# ODS5010 register map
Vendor: OCS; Series: ODS5010; File version: 1.0
CPU: CM0plus r0p0, little endian, MPU, FPU, 4 interrupt priority bits
Registers are 32-bit, read-write, reset 0x0 unless marked. A register's access mark holds for its fields unless they carry their own. Offsets are from the block's base; lines under a group give offsets from that group; [hi:lo] are bit positions; {n}, {i} and the like mark numbered series; 'fields as' and 'values as' point back to an identical list; <NAME> marks a mode.

## Memory map
0x40001C00 TIM13 size 0x24 — Timer 13 Peripheral
0x40002000 TIM14 size 0x24 — Timer 14 Peripheral
0x40003000 IWDG size 0x14 — Independent Watchdog Timer
0x40003800 SPI0 size 0x100 — Serial Peripheral Interface (SPI0) Peripheral
0x40004000 UART0 size 0x30 — Universal Asynchronous Receiver/Transmitter 0
0x40004400 UART1 size 0x30 — Universal Asynchronous Receiver/Transmitter 1
0x40005400 I2C0 size 0x100 — Inter-Integrated Circuit (I2C0) Peripheral
0x40005800 I2C1 size 0x100 — Inter-Integrated Circuit (I2C1) Peripheral
0x40006000 HWMATH size 0x2C — Hardware Mathematical Module, including square root, division, sine and cosine operation functions with status flags
0x40006400 HALL size 0x24 — Hall Sensor
0x40006430 QEP size 0x14 — Quadrature Encoder Pulse
0x40007800 MISC size 0x1C — MISC Control Registers (CSA and Temperature Sensor)
0x40010C00 MCPWM size 0xD0 — Motor Control PWM
0x40012400 ADC size 0x9C — Analog-to-Digital Converter (ADC) Peripheral
0x40013800 SPI1 size 0x100 — Serial Peripheral Interface (SPI1) Peripheral
0x40014000 TIM15 size 0x24 — Timer 15 Peripheral
0x40014400 TIM16 size 0x24 — Timer 16 Peripheral
0x40020000 RCC size 0x80 — Reset and Clock Control (RCC) Module
0x40020400 SYSCFG size 0x400 — System Configuration (SYSCFG) Peripheral
0x40022000 FLASH size 0x100 — Flash Memory Controller Peripheral
0x48000000 GPIO_A size 0x90 — GPIO Port A
0x48000400 GPIO_B size 0x90 — GPIO Port B
0x48000800 GPIO_C size 0x90 — GPIO Port C

## GPIO_A — GPIO Port A
Base 0x48000000; register names take the prefix GPIO_A_
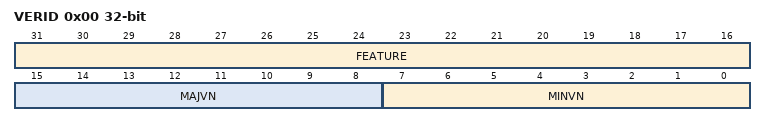
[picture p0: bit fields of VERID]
0x00 VERID ro — Version ID Register
  [31:16] FEATURE — Feature Identification
  [15:8] MAJVN — Major Version Number
  [7:0] MINVN — Minor Version Number
0x04 DR — Data Register
  [15:0] DR — Data Register Value
0x08 DRS — Data Set Register
  [15:0] DRS — Data Set Value
0x0C DRC — Data Clear Register
  [15:0] DRC — Data Clear Value
0x10 DRT — Data Toggle Register
  [15:0] DRT — Data Toggle Value
0x14 OES — Output Enable Set Register
  [15:0] OES — Output Enable Set Value
0x18 OEC — Output Enable Clear Register
  [15:0] OEC — Output Enable Clear Value
0x1C ITES — Interrupt Enable Set Register
  [15:0] ITES — Interrupt Enable Set Value
0x20 ITEC — Interrupt Enable Clear Register
  [15:0] ITEC — Interrupt Enable Clear Value
0x24 ITT0 — Interrupt Type for Pins 0-7
  [31:0] ITT0_7
0x28 ITT1 — Interrupt Type for Pins 8-15
  [31:0] ITT8_15
0x34 ITTC — Interrupt Type Control Register
  [15:0] ITTC — Interrupt Type Control Value
0x38 ITS — Interrupt Status Register
  [15:0] ITS — Interrupt Status Value
0x3C AF0 — Alternate Function for Pins 0-7
  [31:0] AF0_7
0x40 AF1 — Alternate Function for Pins 8-15
  [31:0] AF8_15
0x4C AFC — Alternate Function Control Register
  [15:0] AFC — Alternate Function Control Value
0x50 ANA — Analog Control Register
  [15:0] ANA — Analog Control Value
0x54 ANAC — Analog Control Configuration Register
  [15:0] ANAC — Analog Control Configuration Value
0x58 PU — Pull-up Register
  [15:0] PU — Pull-up Control Value
0x5C SPU — Strong Pull-up Register
  [15:0] SPU — Strong Pull-up Control Value
0x60 PUC — Pull-up Control Register
  [15:0] PUC — Pull-up Control Configuration Value
0x64 PD — Pull-down Register
  [15:0] PD — Pull-down Control Value
0x68 PDC — Pull-down Control Register
  [15:0] PDC — Pull-down Control Configuration Value
0x6C DRVS0 — Drive Strength for Pins 0-7
  [31:0] DRVS0_7
0x70 DRVS1 — Drive Strength for Pins 8-15
  [31:0] DRVS8_15
0x7C DRVC — Drive Strength Control Register
  [15:0] DRVC — Drive Strength Control Value
0x80 SLS — Slew Rate Set Register
  [15:0] SL — Slew Rate Set Value
0x84 SLC — Slew Rate Control Register
  [15:0] SLC — Slew Rate Control Value
0x88 STS — Schmitt Trigger Set Register
  [15:0] ST — Schmitt Trigger Set Value
0x8C STC — Schmitt Trigger Control Register
  [15:0] STC — Schmitt Trigger Control Value

## GPIO_B — GPIO Port B
Base 0x48000400; register names take the prefix GPIO_B_
Registers as GPIO_A.

## GPIO_C — GPIO Port C
Base 0x48000800; register names take the prefix GPIO_C_
Registers as GPIO_A.
